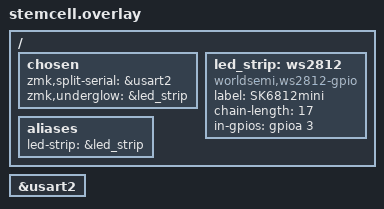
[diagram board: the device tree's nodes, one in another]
/*
 * Copyright (c) 2022 Megamind
 *
 * SPDX-License-Identifier: MIT
 */

#include <dt-bindings/gpio/gpio.h>

/ {
	chosen {
		zmk,split-serial = &usart2;
		zmk,underglow = &led_strip;
	};
};

&usart2 {
	status = "okay";
};


/ {
    led_strip: ws2812 {
        compatible = "worldsemi,ws2812-gpio";
        label = "SK6812mini";

        chain-length = <17>;
        in-gpios = <&gpioa 3 0>;
    };

    aliases {
        led-strip = &led_strip;
    };
};
